VERSION ""

NS_ :

BS_:

BU_: BMS_Controller CAN_Receiver

BA_DEF_ BO_  "VFrameFormat" ENUM  "StandardCAN","ExtendedCAN";

BA_DEF_DEF_  "VFrameFormat" "StandardCAN";

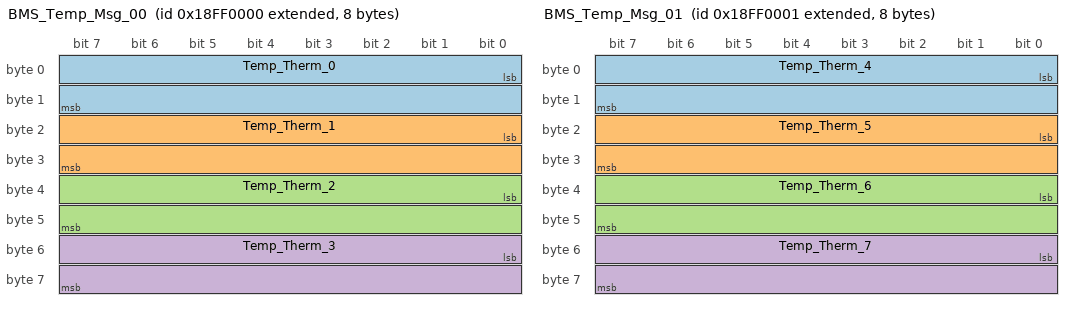
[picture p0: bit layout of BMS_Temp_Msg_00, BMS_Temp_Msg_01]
BO_ 2566848512 BMS_Temp_Msg_00: 8 BMS_Controller
 SG_ Temp_Therm_0 : 0|16@1- (0.1,0) [-40|125] "degC"  CAN_Receiver
 SG_ Temp_Therm_1 : 16|16@1- (0.1,0) [-40|125] "degC"  CAN_Receiver
 SG_ Temp_Therm_2 : 32|16@1- (0.1,0) [-40|125] "degC"  CAN_Receiver
 SG_ Temp_Therm_3 : 48|16@1- (0.1,0) [-40|125] "degC"  CAN_Receiver

BO_ 2566848513 BMS_Temp_Msg_01: 8 BMS_Controller
 SG_ Temp_Therm_4 : 0|16@1- (0.1,0) [-40|125] "degC"  CAN_Receiver
 SG_ Temp_Therm_5 : 16|16@1- (0.1,0) [-40|125] "degC"  CAN_Receiver
 SG_ Temp_Therm_6 : 32|16@1- (0.1,0) [-40|125] "degC"  CAN_Receiver
 SG_ Temp_Therm_7 : 48|16@1- (0.1,0) [-40|125] "degC"  CAN_Receiver

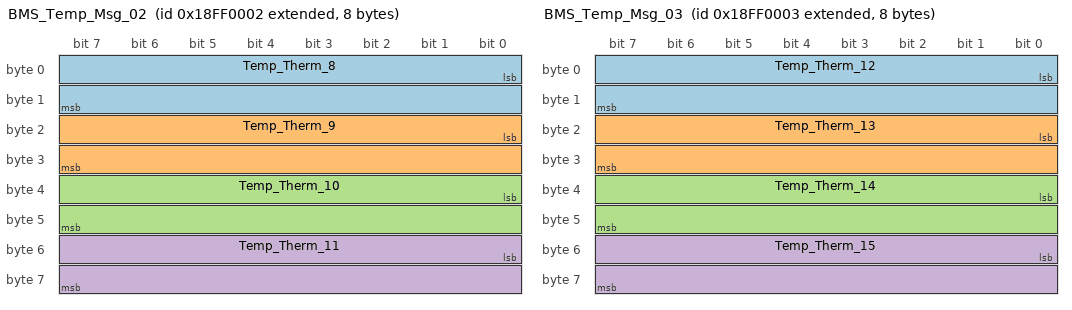
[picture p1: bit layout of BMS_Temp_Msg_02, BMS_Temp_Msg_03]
BO_ 2566848514 BMS_Temp_Msg_02: 8 BMS_Controller
 SG_ Temp_Therm_8 : 0|16@1- (0.1,0) [-40|125] "degC"  CAN_Receiver
 SG_ Temp_Therm_9 : 16|16@1- (0.1,0) [-40|125] "degC"  CAN_Receiver
 SG_ Temp_Therm_10 : 32|16@1- (0.1,0) [-40|125] "degC"  CAN_Receiver
 SG_ Temp_Therm_11 : 48|16@1- (0.1,0) [-40|125] "degC"  CAN_Receiver

BO_ 2566848515 BMS_Temp_Msg_03: 8 BMS_Controller
 SG_ Temp_Therm_12 : 0|16@1- (0.1,0) [-40|125] "degC"  CAN_Receiver
 SG_ Temp_Therm_13 : 16|16@1- (0.1,0) [-40|125] "degC"  CAN_Receiver
 SG_ Temp_Therm_14 : 32|16@1- (0.1,0) [-40|125] "degC"  CAN_Receiver
 SG_ Temp_Therm_15 : 48|16@1- (0.1,0) [-40|125] "degC"  CAN_Receiver

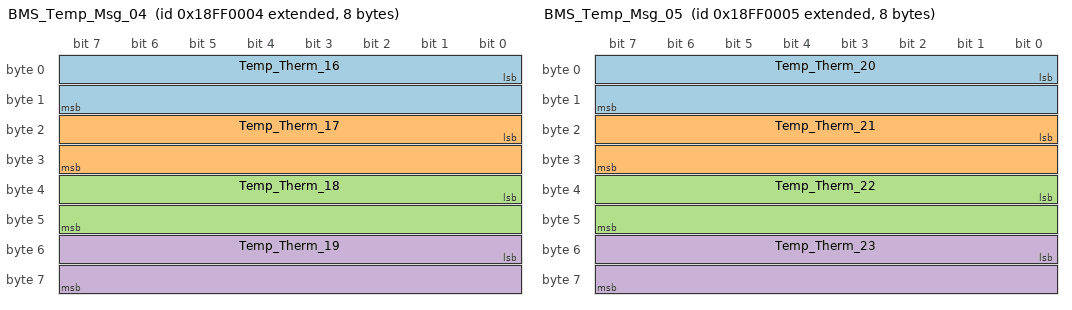
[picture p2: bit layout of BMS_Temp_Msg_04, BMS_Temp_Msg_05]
BO_ 2566848516 BMS_Temp_Msg_04: 8 BMS_Controller
 SG_ Temp_Therm_16 : 0|16@1- (0.1,0) [-40|125] "degC"  CAN_Receiver
 SG_ Temp_Therm_17 : 16|16@1- (0.1,0) [-40|125] "degC"  CAN_Receiver
 SG_ Temp_Therm_18 : 32|16@1- (0.1,0) [-40|125] "degC"  CAN_Receiver
 SG_ Temp_Therm_19 : 48|16@1- (0.1,0) [-40|125] "degC"  CAN_Receiver

BO_ 2566848517 BMS_Temp_Msg_05: 8 BMS_Controller
 SG_ Temp_Therm_20 : 0|16@1- (0.1,0) [-40|125] "degC"  CAN_Receiver
 SG_ Temp_Therm_21 : 16|16@1- (0.1,0) [-40|125] "degC"  CAN_Receiver
 SG_ Temp_Therm_22 : 32|16@1- (0.1,0) [-40|125] "degC"  CAN_Receiver
 SG_ Temp_Therm_23 : 48|16@1- (0.1,0) [-40|125] "degC"  CAN_Receiver

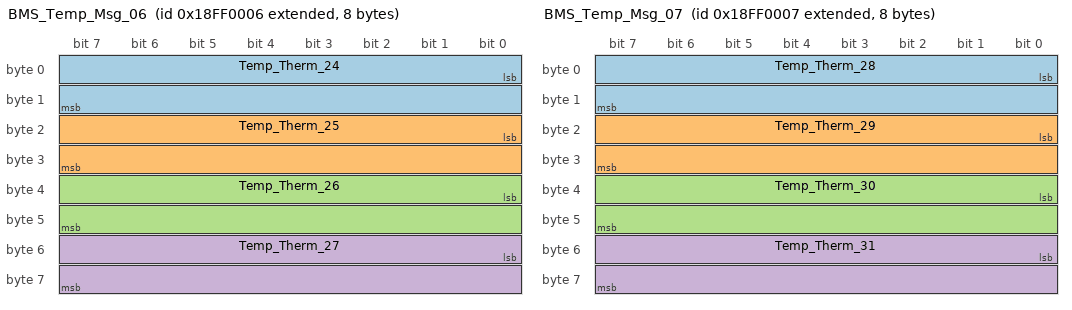
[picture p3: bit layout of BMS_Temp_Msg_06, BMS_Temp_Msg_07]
BO_ 2566848518 BMS_Temp_Msg_06: 8 BMS_Controller
 SG_ Temp_Therm_24 : 0|16@1- (0.1,0) [-40|125] "degC"  CAN_Receiver
 SG_ Temp_Therm_25 : 16|16@1- (0.1,0) [-40|125] "degC"  CAN_Receiver
 SG_ Temp_Therm_26 : 32|16@1- (0.1,0) [-40|125] "degC"  CAN_Receiver
 SG_ Temp_Therm_27 : 48|16@1- (0.1,0) [-40|125] "degC"  CAN_Receiver

BO_ 2566848519 BMS_Temp_Msg_07: 8 BMS_Controller
 SG_ Temp_Therm_28 : 0|16@1- (0.1,0) [-40|125] "degC"  CAN_Receiver
 SG_ Temp_Therm_29 : 16|16@1- (0.1,0) [-40|125] "degC"  CAN_Receiver
 SG_ Temp_Therm_30 : 32|16@1- (0.1,0) [-40|125] "degC"  CAN_Receiver
 SG_ Temp_Therm_31 : 48|16@1- (0.1,0) [-40|125] "degC"  CAN_Receiver

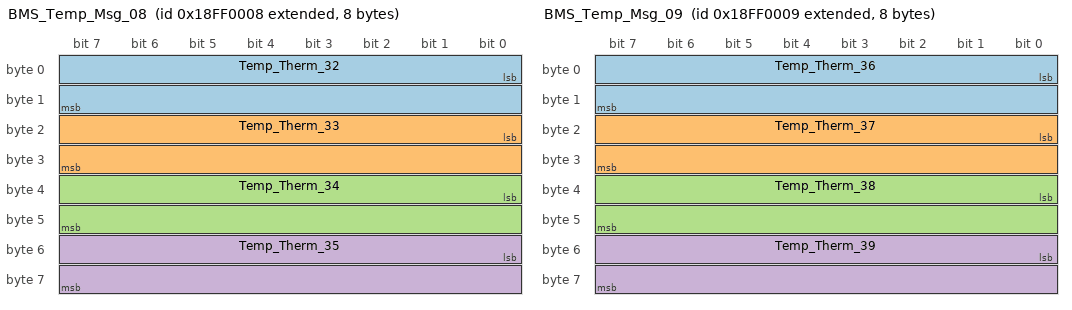
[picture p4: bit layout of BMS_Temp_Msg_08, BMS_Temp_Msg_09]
BO_ 2566848520 BMS_Temp_Msg_08: 8 BMS_Controller
 SG_ Temp_Therm_32 : 0|16@1- (0.1,0) [-40|125] "degC"  CAN_Receiver
 SG_ Temp_Therm_33 : 16|16@1- (0.1,0) [-40|125] "degC"  CAN_Receiver
 SG_ Temp_Therm_34 : 32|16@1- (0.1,0) [-40|125] "degC"  CAN_Receiver
 SG_ Temp_Therm_35 : 48|16@1- (0.1,0) [-40|125] "degC"  CAN_Receiver

BO_ 2566848521 BMS_Temp_Msg_09: 8 BMS_Controller
 SG_ Temp_Therm_36 : 0|16@1- (0.1,0) [-40|125] "degC"  CAN_Receiver
 SG_ Temp_Therm_37 : 16|16@1- (0.1,0) [-40|125] "degC"  CAN_Receiver
 SG_ Temp_Therm_38 : 32|16@1- (0.1,0) [-40|125] "degC"  CAN_Receiver
 SG_ Temp_Therm_39 : 48|16@1- (0.1,0) [-40|125] "degC"  CAN_Receiver

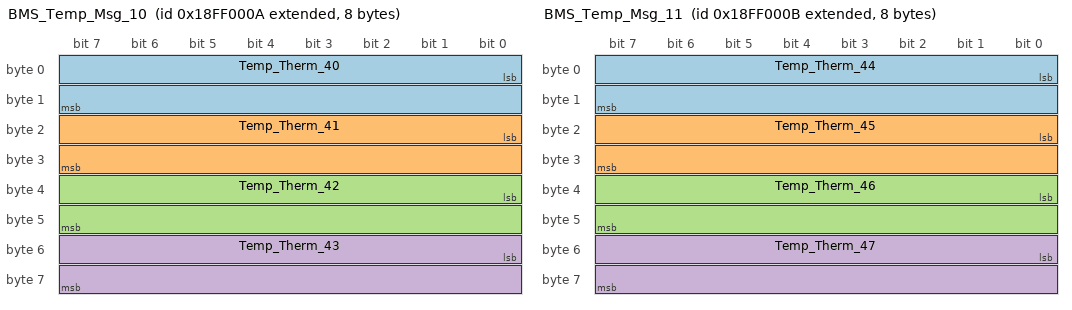
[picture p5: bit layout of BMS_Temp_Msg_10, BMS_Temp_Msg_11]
BO_ 2566848522 BMS_Temp_Msg_10: 8 BMS_Controller
 SG_ Temp_Therm_40 : 0|16@1- (0.1,0) [-40|125] "degC"  CAN_Receiver
 SG_ Temp_Therm_41 : 16|16@1- (0.1,0) [-40|125] "degC"  CAN_Receiver
 SG_ Temp_Therm_42 : 32|16@1- (0.1,0) [-40|125] "degC"  CAN_Receiver
 SG_ Temp_Therm_43 : 48|16@1- (0.1,0) [-40|125] "degC"  CAN_Receiver

BO_ 2566848523 BMS_Temp_Msg_11: 8 BMS_Controller
 SG_ Temp_Therm_44 : 0|16@1- (0.1,0) [-40|125] "degC"  CAN_Receiver
 SG_ Temp_Therm_45 : 16|16@1- (0.1,0) [-40|125] "degC"  CAN_Receiver
 SG_ Temp_Therm_46 : 32|16@1- (0.1,0) [-40|125] "degC"  CAN_Receiver
 SG_ Temp_Therm_47 : 48|16@1- (0.1,0) [-40|125] "degC"  CAN_Receiver

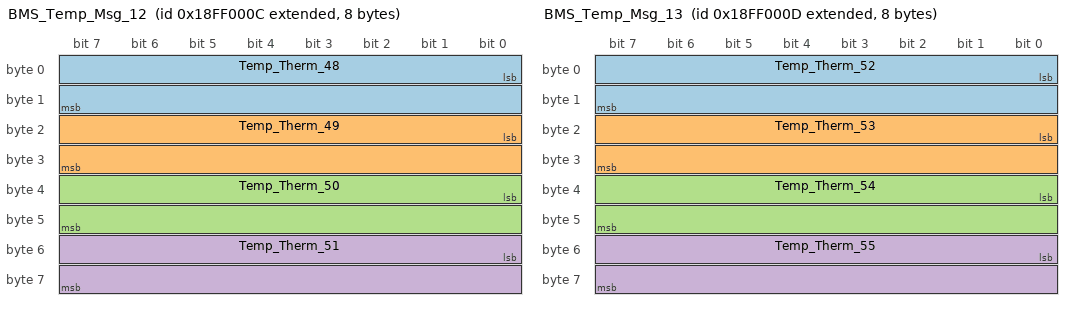
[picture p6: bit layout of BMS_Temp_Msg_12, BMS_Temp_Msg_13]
BO_ 2566848524 BMS_Temp_Msg_12: 8 BMS_Controller
 SG_ Temp_Therm_48 : 0|16@1- (0.1,0) [-40|125] "degC"  CAN_Receiver
 SG_ Temp_Therm_49 : 16|16@1- (0.1,0) [-40|125] "degC"  CAN_Receiver
 SG_ Temp_Therm_50 : 32|16@1- (0.1,0) [-40|125] "degC"  CAN_Receiver
 SG_ Temp_Therm_51 : 48|16@1- (0.1,0) [-40|125] "degC"  CAN_Receiver

BO_ 2566848525 BMS_Temp_Msg_13: 8 BMS_Controller
 SG_ Temp_Therm_52 : 0|16@1- (0.1,0) [-40|125] "degC"  CAN_Receiver
 SG_ Temp_Therm_53 : 16|16@1- (0.1,0) [-40|125] "degC"  CAN_Receiver
 SG_ Temp_Therm_54 : 32|16@1- (0.1,0) [-40|125] "degC"  CAN_Receiver
 SG_ Temp_Therm_55 : 48|16@1- (0.1,0) [-40|125] "degC"  CAN_Receiver

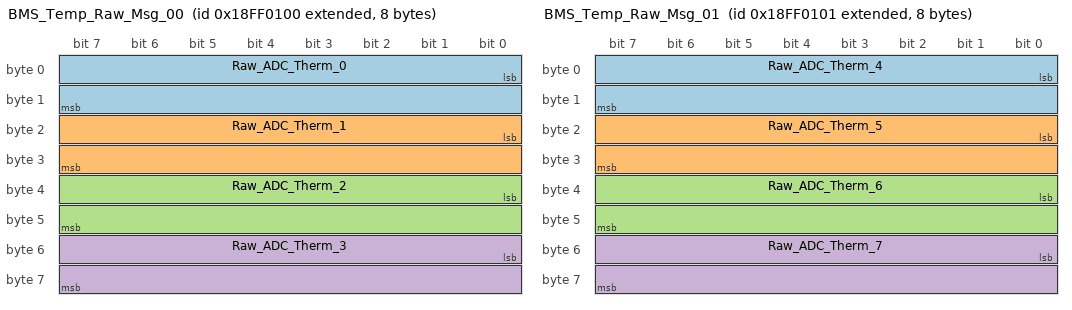
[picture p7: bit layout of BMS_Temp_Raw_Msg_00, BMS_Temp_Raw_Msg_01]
BO_ 2566848768 BMS_Temp_Raw_Msg_00: 8 BMS_Controller
 SG_ Raw_ADC_Therm_0 : 0|16@1+ (1,0) [0|4095] ""  CAN_Receiver
 SG_ Raw_ADC_Therm_1 : 16|16@1+ (1,0) [0|4095] ""  CAN_Receiver
 SG_ Raw_ADC_Therm_2 : 32|16@1+ (1,0) [0|4095] ""  CAN_Receiver
 SG_ Raw_ADC_Therm_3 : 48|16@1+ (1,0) [0|4095] ""  CAN_Receiver

BO_ 2566848769 BMS_Temp_Raw_Msg_01: 8 BMS_Controller
 SG_ Raw_ADC_Therm_4 : 0|16@1+ (1,0) [0|4095] ""  CAN_Receiver
 SG_ Raw_ADC_Therm_5 : 16|16@1+ (1,0) [0|4095] ""  CAN_Receiver
 SG_ Raw_ADC_Therm_6 : 32|16@1+ (1,0) [0|4095] ""  CAN_Receiver
 SG_ Raw_ADC_Therm_7 : 48|16@1+ (1,0) [0|4095] ""  CAN_Receiver

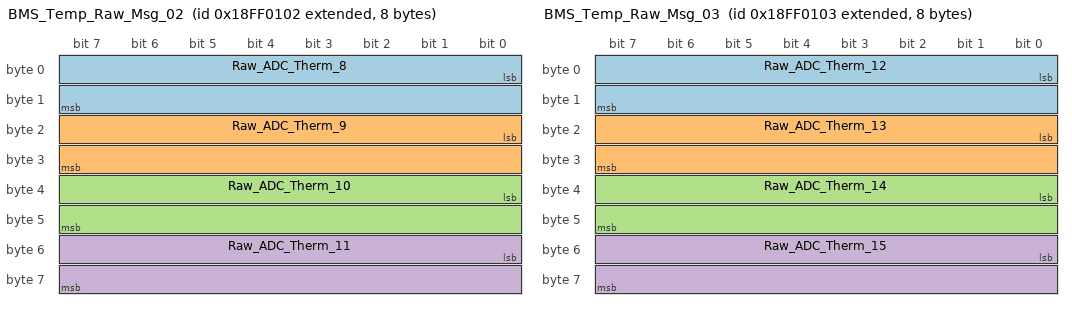
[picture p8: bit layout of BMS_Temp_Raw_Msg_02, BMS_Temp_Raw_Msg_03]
BO_ 2566848770 BMS_Temp_Raw_Msg_02: 8 BMS_Controller
 SG_ Raw_ADC_Therm_8 : 0|16@1+ (1,0) [0|4095] ""  CAN_Receiver
 SG_ Raw_ADC_Therm_9 : 16|16@1+ (1,0) [0|4095] ""  CAN_Receiver
 SG_ Raw_ADC_Therm_10 : 32|16@1+ (1,0) [0|4095] ""  CAN_Receiver
 SG_ Raw_ADC_Therm_11 : 48|16@1+ (1,0) [0|4095] ""  CAN_Receiver

BO_ 2566848771 BMS_Temp_Raw_Msg_03: 8 BMS_Controller
 SG_ Raw_ADC_Therm_12 : 0|16@1+ (1,0) [0|4095] ""  CAN_Receiver
 SG_ Raw_ADC_Therm_13 : 16|16@1+ (1,0) [0|4095] ""  CAN_Receiver
 SG_ Raw_ADC_Therm_14 : 32|16@1+ (1,0) [0|4095] ""  CAN_Receiver
 SG_ Raw_ADC_Therm_15 : 48|16@1+ (1,0) [0|4095] ""  CAN_Receiver

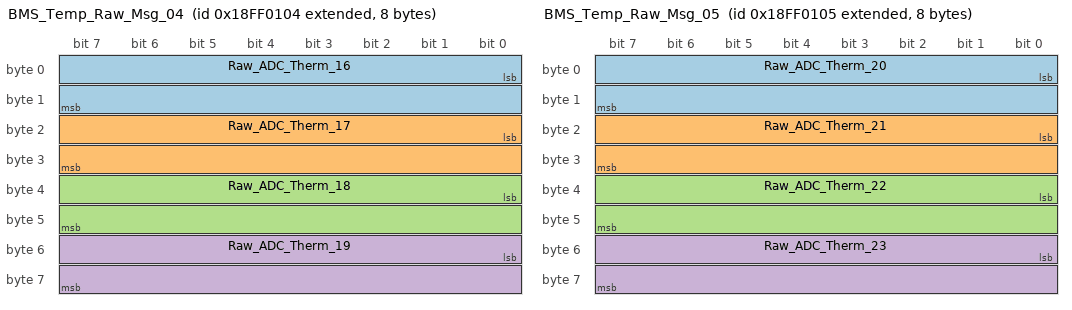
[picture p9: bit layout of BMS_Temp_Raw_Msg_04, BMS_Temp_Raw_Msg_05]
BO_ 2566848772 BMS_Temp_Raw_Msg_04: 8 BMS_Controller
 SG_ Raw_ADC_Therm_16 : 0|16@1+ (1,0) [0|4095] ""  CAN_Receiver
 SG_ Raw_ADC_Therm_17 : 16|16@1+ (1,0) [0|4095] ""  CAN_Receiver
 SG_ Raw_ADC_Therm_18 : 32|16@1+ (1,0) [0|4095] ""  CAN_Receiver
 SG_ Raw_ADC_Therm_19 : 48|16@1+ (1,0) [0|4095] ""  CAN_Receiver

BO_ 2566848773 BMS_Temp_Raw_Msg_05: 8 BMS_Controller
 SG_ Raw_ADC_Therm_20 : 0|16@1+ (1,0) [0|4095] ""  CAN_Receiver
 SG_ Raw_ADC_Therm_21 : 16|16@1+ (1,0) [0|4095] ""  CAN_Receiver
 SG_ Raw_ADC_Therm_22 : 32|16@1+ (1,0) [0|4095] ""  CAN_Receiver
 SG_ Raw_ADC_Therm_23 : 48|16@1+ (1,0) [0|4095] ""  CAN_Receiver

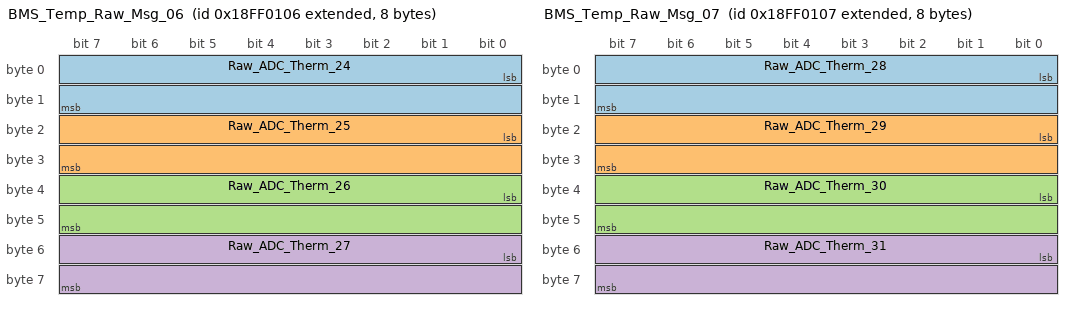
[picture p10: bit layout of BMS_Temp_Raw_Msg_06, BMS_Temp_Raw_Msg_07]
BO_ 2566848774 BMS_Temp_Raw_Msg_06: 8 BMS_Controller
 SG_ Raw_ADC_Therm_24 : 0|16@1+ (1,0) [0|4095] ""  CAN_Receiver
 SG_ Raw_ADC_Therm_25 : 16|16@1+ (1,0) [0|4095] ""  CAN_Receiver
 SG_ Raw_ADC_Therm_26 : 32|16@1+ (1,0) [0|4095] ""  CAN_Receiver
 SG_ Raw_ADC_Therm_27 : 48|16@1+ (1,0) [0|4095] ""  CAN_Receiver

BO_ 2566848775 BMS_Temp_Raw_Msg_07: 8 BMS_Controller
 SG_ Raw_ADC_Therm_28 : 0|16@1+ (1,0) [0|4095] ""  CAN_Receiver
 SG_ Raw_ADC_Therm_29 : 16|16@1+ (1,0) [0|4095] ""  CAN_Receiver
 SG_ Raw_ADC_Therm_30 : 32|16@1+ (1,0) [0|4095] ""  CAN_Receiver
 SG_ Raw_ADC_Therm_31 : 48|16@1+ (1,0) [0|4095] ""  CAN_Receiver

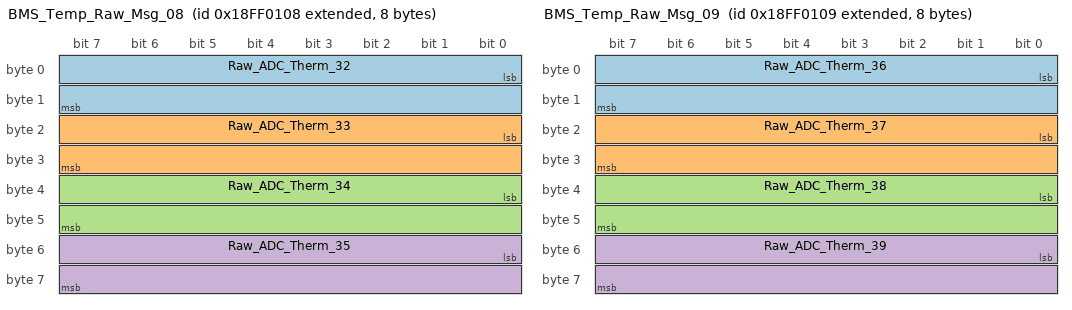
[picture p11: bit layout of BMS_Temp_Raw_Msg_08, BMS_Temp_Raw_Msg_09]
BO_ 2566848776 BMS_Temp_Raw_Msg_08: 8 BMS_Controller
 SG_ Raw_ADC_Therm_32 : 0|16@1+ (1,0) [0|4095] ""  CAN_Receiver
 SG_ Raw_ADC_Therm_33 : 16|16@1+ (1,0) [0|4095] ""  CAN_Receiver
 SG_ Raw_ADC_Therm_34 : 32|16@1+ (1,0) [0|4095] ""  CAN_Receiver
 SG_ Raw_ADC_Therm_35 : 48|16@1+ (1,0) [0|4095] ""  CAN_Receiver

BO_ 2566848777 BMS_Temp_Raw_Msg_09: 8 BMS_Controller
 SG_ Raw_ADC_Therm_36 : 0|16@1+ (1,0) [0|4095] ""  CAN_Receiver
 SG_ Raw_ADC_Therm_37 : 16|16@1+ (1,0) [0|4095] ""  CAN_Receiver
 SG_ Raw_ADC_Therm_38 : 32|16@1+ (1,0) [0|4095] ""  CAN_Receiver
 SG_ Raw_ADC_Therm_39 : 48|16@1+ (1,0) [0|4095] ""  CAN_Receiver

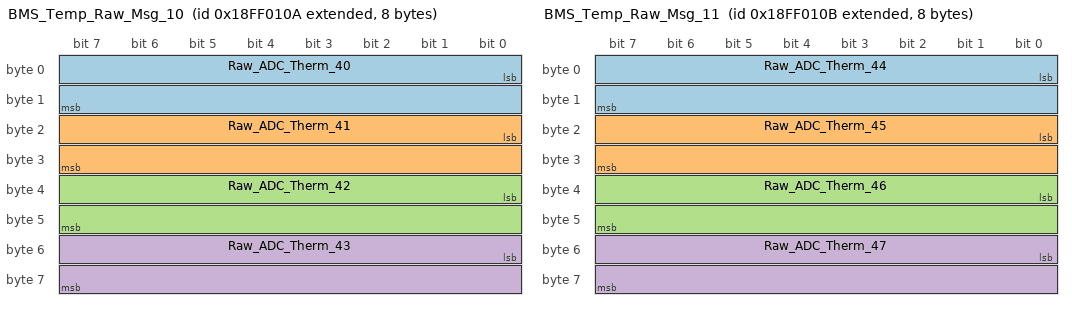
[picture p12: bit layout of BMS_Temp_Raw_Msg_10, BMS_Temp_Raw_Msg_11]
BO_ 2566848778 BMS_Temp_Raw_Msg_10: 8 BMS_Controller
 SG_ Raw_ADC_Therm_40 : 0|16@1+ (1,0) [0|4095] ""  CAN_Receiver
 SG_ Raw_ADC_Therm_41 : 16|16@1+ (1,0) [0|4095] ""  CAN_Receiver
 SG_ Raw_ADC_Therm_42 : 32|16@1+ (1,0) [0|4095] ""  CAN_Receiver
 SG_ Raw_ADC_Therm_43 : 48|16@1+ (1,0) [0|4095] ""  CAN_Receiver

BO_ 2566848779 BMS_Temp_Raw_Msg_11: 8 BMS_Controller
 SG_ Raw_ADC_Therm_44 : 0|16@1+ (1,0) [0|4095] ""  CAN_Receiver
 SG_ Raw_ADC_Therm_45 : 16|16@1+ (1,0) [0|4095] ""  CAN_Receiver
 SG_ Raw_ADC_Therm_46 : 32|16@1+ (1,0) [0|4095] ""  CAN_Receiver
 SG_ Raw_ADC_Therm_47 : 48|16@1+ (1,0) [0|4095] ""  CAN_Receiver

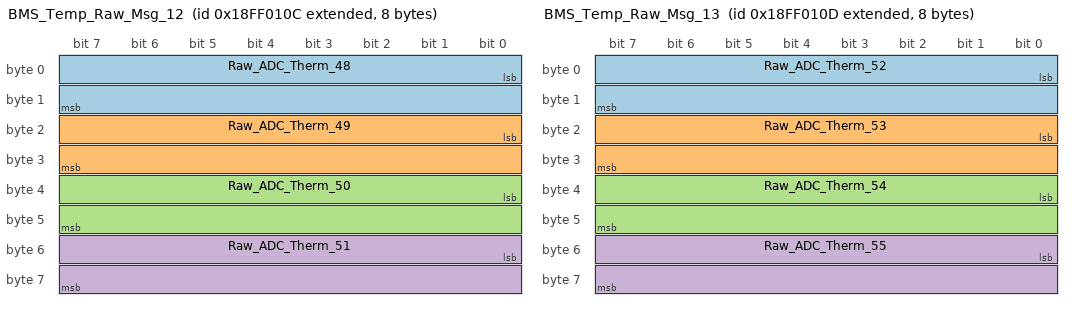
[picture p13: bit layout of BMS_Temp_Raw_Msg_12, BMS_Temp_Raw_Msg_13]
BO_ 2566848780 BMS_Temp_Raw_Msg_12: 8 BMS_Controller
 SG_ Raw_ADC_Therm_48 : 0|16@1+ (1,0) [0|4095] ""  CAN_Receiver
 SG_ Raw_ADC_Therm_49 : 16|16@1+ (1,0) [0|4095] ""  CAN_Receiver
 SG_ Raw_ADC_Therm_50 : 32|16@1+ (1,0) [0|4095] ""  CAN_Receiver
 SG_ Raw_ADC_Therm_51 : 48|16@1+ (1,0) [0|4095] ""  CAN_Receiver

BO_ 2566848781 BMS_Temp_Raw_Msg_13: 8 BMS_Controller
 SG_ Raw_ADC_Therm_52 : 0|16@1+ (1,0) [0|4095] ""  CAN_Receiver
 SG_ Raw_ADC_Therm_53 : 16|16@1+ (1,0) [0|4095] ""  CAN_Receiver
 SG_ Raw_ADC_Therm_54 : 32|16@1+ (1,0) [0|4095] ""  CAN_Receiver
 SG_ Raw_ADC_Therm_55 : 48|16@1+ (1,0) [0|4095] ""  CAN_Receiver

CM_ BO_ 2566848512 "Temperature readings for thermistors 0-3. Each value is temperature * 10 (0.1C resolution). 0x8000 = invalid/no reading";
CM_ BO_ 2566848513 "Temperature readings for thermistors 4-7";
CM_ BO_ 2566848514 "Temperature readings for thermistors 8-11";
CM_ BO_ 2566848515 "Temperature readings for thermistors 12-15";
CM_ BO_ 2566848516 "Temperature readings for thermistors 16-19";
CM_ BO_ 2566848517 "Temperature readings for thermistors 20-23";
CM_ BO_ 2566848518 "Temperature readings for thermistors 24-27";
CM_ BO_ 2566848519 "Temperature readings for thermistors 28-31";
CM_ BO_ 2566848520 "Temperature readings for thermistors 32-35";
CM_ BO_ 2566848521 "Temperature readings for thermistors 36-39";
CM_ BO_ 2566848522 "Temperature readings for thermistors 40-43";
CM_ BO_ 2566848523 "Temperature readings for thermistors 44-47";
CM_ BO_ 2566848524 "Temperature readings for thermistors 48-51";
CM_ BO_ 2566848525 "Temperature readings for thermistors 52-55";
CM_ BO_ 2566848768 "Raw ADC readings for diagnostic purposes - thermistors 0-3 (12-bit ADC values)";
CM_ BO_ 2566848769 "Raw ADC readings for diagnostic purposes - thermistors 4-7";
CM_ BO_ 2566848770 "Raw ADC readings for diagnostic purposes - thermistors 8-11";
CM_ BO_ 2566848771 "Raw ADC readings for diagnostic purposes - thermistors 12-15";
CM_ BO_ 2566848772 "Raw ADC readings for diagnostic purposes - thermistors 16-19";
CM_ BO_ 2566848773 "Raw ADC readings for diagnostic purposes - thermistors 20-23";
CM_ BO_ 2566848774 "Raw ADC readings for diagnostic purposes - thermistors 24-27";
CM_ BO_ 2566848775 "Raw ADC readings for diagnostic purposes - thermistors 28-31";
CM_ BO_ 2566848776 "Raw ADC readings for diagnostic purposes - thermistors 32-35";
CM_ BO_ 2566848777 "Raw ADC readings for diagnostic purposes - thermistors 36-39";
CM_ BO_ 2566848778 "Raw ADC readings for diagnostic purposes - thermistors 40-43";
CM_ BO_ 2566848779 "Raw ADC readings for diagnostic purposes - thermistors 44-47";
CM_ BO_ 2566848780 "Raw ADC readings for diagnostic purposes - thermistors 48-51";
CM_ BO_ 2566848781 "Raw ADC readings for diagnostic purposes - thermistors 52-55";

BA_DEF_ "BusType" STRING ;
BA_DEF_ BO_ "GenMsgCycleTime" INT 0 10000;
BA_DEF_DEF_ "BusType" "CAN";
BA_DEF_DEF_ "GenMsgCycleTime" 0;

BA_ "GenMsgCycleTime" BO_ 2566848512 1000;
BA_ "GenMsgCycleTime" BO_ 2566848513 1000;
BA_ "GenMsgCycleTime" BO_ 2566848514 1000;
BA_ "GenMsgCycleTime" BO_ 2566848515 1000;
BA_ "GenMsgCycleTime" BO_ 2566848516 1000;
BA_ "GenMsgCycleTime" BO_ 2566848517 1000;
BA_ "GenMsgCycleTime" BO_ 2566848518 1000;
BA_ "GenMsgCycleTime" BO_ 2566848519 1000;
BA_ "GenMsgCycleTime" BO_ 2566848520 1000;
BA_ "GenMsgCycleTime" BO_ 2566848521 1000;
BA_ "GenMsgCycleTime" BO_ 2566848522 1000;
BA_ "GenMsgCycleTime" BO_ 2566848523 1000;
BA_ "GenMsgCycleTime" BO_ 2566848524 1000;
BA_ "GenMsgCycleTime" BO_ 2566848525 1000;

BA_ "VFrameFormat" BO_ 2566848512 1;
BA_ "VFrameFormat" BO_ 2566848513 1;
BA_ "VFrameFormat" BO_ 2566848514 1;
BA_ "VFrameFormat" BO_ 2566848515 1;
BA_ "VFrameFormat" BO_ 2566848516 1;
BA_ "VFrameFormat" BO_ 2566848517 1;
BA_ "VFrameFormat" BO_ 2566848518 1;
BA_ "VFrameFormat" BO_ 2566848519 1;
BA_ "VFrameFormat" BO_ 2566848520 1;
BA_ "VFrameFormat" BO_ 2566848521 1;
BA_ "VFrameFormat" BO_ 2566848522 1;
BA_ "VFrameFormat" BO_ 2566848523 1;
BA_ "VFrameFormat" BO_ 2566848524 1;
BA_ "VFrameFormat" BO_ 2566848525 1;
BA_ "VFrameFormat" BO_ 2566848768 1;
BA_ "VFrameFormat" BO_ 2566848769 1;
BA_ "VFrameFormat" BO_ 2566848770 1;
BA_ "VFrameFormat" BO_ 2566848771 1;
BA_ "VFrameFormat" BO_ 2566848772 1;
BA_ "VFrameFormat" BO_ 2566848773 1;
BA_ "VFrameFormat" BO_ 2566848774 1;
BA_ "VFrameFormat" BO_ 2566848775 1;
BA_ "VFrameFormat" BO_ 2566848776 1;
BA_ "VFrameFormat" BO_ 2566848777 1;
BA_ "VFrameFormat" BO_ 2566848778 1;
BA_ "VFrameFormat" BO_ 2566848779 1;
BA_ "VFrameFormat" BO_ 2566848780 1;
BA_ "VFrameFormat" BO_ 2566848781 1;
